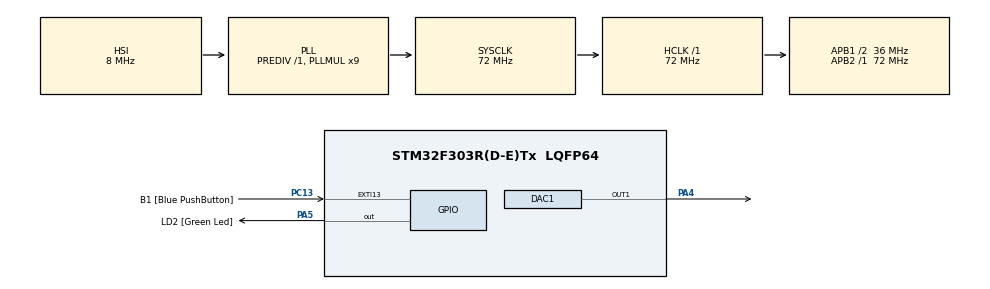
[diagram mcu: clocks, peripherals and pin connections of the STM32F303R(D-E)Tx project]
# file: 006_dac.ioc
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Mcu.Family=STM32F3
RCC.CortexFreq_Value=72000000
PC13.Signal=GPXTI13
PA14.GPIO_Label=TCK
RCC.SYSCLKSourceVirtual=RCC_SYSCLKSOURCE_PLLCLK
PC13.GPIO_Label=B1 [Blue PushButton]
RCC.APB1CLKDivider=RCC_HCLK_DIV2
PC14-OSC32_IN.Signal=RCC_OSC32_IN
ProjectManager.StackSize=0x400
PA13.Signal=SYS_JTMS-SWDIO
ProjectManager.TargetToolchain=STM32CubeIDE
SH.COMP_DAC11_group.0=DAC1_OUT1,DAC_OUT1
RCC.HCLKFreq_Value=72000000
RCC.APB2TimFreq_Value=72000000
RCC.USBFreq_Value=72000000
PC15-OSC32_OUT.Signal=RCC_OSC32_OUT
RCC.AHBFreq_Value=72000000
PF0-OSC_IN.Mode=HSE-External-Oscillator
PA5.Signal=GPIO_Output
RCC.HSE_VALUE=8000000
board=NUCLEO-F303RE
RCC.RCC_PLLsource_Clock_Source_FROM_HSE=RCC_HSE_PREDIV_DIV2
RCC.PLLMUL=RCC_PLL_MUL9
RCC.APB2Freq_Value=72000000
PA14.Mode=Serial_Wire
PA5.GPIO_PuPd=GPIO_NOPULL
PA13.Mode=Serial_Wire
Mcu.Name=STM32F303R(D-E)Tx
PA13.GPIO_Label=TMS
PB3.Signal=SYS_JTDO-TRACESWO
PA4.Signal=COMP_DAC11_group
RCC.SYSCLKFreq_VALUE=72000000
Mcu.Package=LQFP64
PA5.GPIO_Label=LD2 [Green Led]
PC13.GPIO_ModeDefaultEXTI=GPIO_MODE_IT_FALLING
PA14.Signal=SYS_JTCK-SWCLK
ProjectManager.HeapSize=0x200
RCC.HSI_VALUE=8000000
RCC.PLLP=RCC_PLLP_DIV4
PA5.GPIO_Speed=GPIO_SPEED_FREQ_LOW
RCC.PLLQ=7
NVIC.PriorityGroup=NVIC_PRIORITYGROUP_0
RCC.PLLM=8
RCC.PLLN=336
RCC.APB1TimFreq_Value=72000000
PF0-OSC_IN.Signal=RCC_OSC_IN
PF1-OSC_OUT.Mode=HSE-External-Oscillator
RCC.APB1Freq_Value=36000000
PA5.GPIO_Mode=GPIO_MODE_OUTPUT_PP
PF1-OSC_OUT.Signal=RCC_OSC_OUT
PB3.GPIO_Label=SWO

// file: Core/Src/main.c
/* USER CODE BEGIN Header */
/**
  ******************************************************************************
  * @file           : main.c
  * @brief          : Main program body
  ******************************************************************************
  * @attention
  *
  * <h2><center>&copy; Copyright (c) 2021 STMicroelectronics.
  * All rights reserved.</center></h2>
  *
  * This software component is licensed by ST under BSD 3-Clause license,
  * the "License"; You may not use this file except in compliance with the
  * License. You may obtain a copy of the License at:
  *                        opensource.org/licenses/BSD-3-Clause
  *
  ******************************************************************************
  */
/* USER CODE END Header */
#include "main.h"

DAC_HandleTypeDef hdac1;
uint16_t dac_value;

void SystemClock_Config(void);
static void MX_GPIO_Init(void);
static void MX_DAC1_Init(void);

int main(void)
{

  /* MCU Configuration--------------------------------------------------------*/

  /* Reset of all peripherals, Initializes the Flash interface and the Systick. */
  HAL_Init();

  /* Configure the system clock */
  SystemClock_Config();

  /* Initialize all configured peripherals */
  MX_GPIO_Init();
  MX_DAC1_Init();
  /* USER CODE BEGIN 2 */
  HAL_DAC_SetValue(&hdac1, DAC1_CHANNEL_1, DAC_ALIGN_12B_R, 4090);
  HAL_DAC_Start(&hdac1, DAC1_CHANNEL_1);

  /* USER CODE END 2 */

  /* Infinite loop */
  while (1)
  {

    /* USER CODE BEGIN 3 */
	  dac_value=HAL_DAC_GetValue(&hdac1, DAC1_CHANNEL_1);
  }
  /* USER CODE END 3 */
}

void SystemClock_Config(void)
{
  RCC_OscInitTypeDef RCC_OscInitStruct = {0};
  RCC_ClkInitTypeDef RCC_ClkInitStruct = {0};

  /** Initializes the RCC Oscillators according to the specified parameters
  * in the RCC_OscInitTypeDef structure.
  */
  RCC_OscInitStruct.OscillatorType = RCC_OSCILLATORTYPE_HSI;
  RCC_OscInitStruct.HSIState = RCC_HSI_ON;
  RCC_OscInitStruct.HSICalibrationValue = RCC_HSICALIBRATION_DEFAULT;
  RCC_OscInitStruct.PLL.PLLState = RCC_PLL_ON;
  RCC_OscInitStruct.PLL.PLLSource = RCC_PLLSOURCE_HSI;
  RCC_OscInitStruct.PLL.PLLMUL = RCC_PLL_MUL9;
  RCC_OscInitStruct.PLL.PREDIV = RCC_PREDIV_DIV1;
  if (HAL_RCC_OscConfig(&RCC_OscInitStruct) != HAL_OK)
  {
    Error_Handler();
  }
  /** Initializes the CPU, AHB and APB buses clocks
  */
  RCC_ClkInitStruct.ClockType = RCC_CLOCKTYPE_HCLK|RCC_CLOCKTYPE_SYSCLK
                              |RCC_CLOCKTYPE_PCLK1|RCC_CLOCKTYPE_PCLK2;
  RCC_ClkInitStruct.SYSCLKSource = RCC_SYSCLKSOURCE_PLLCLK;
  RCC_ClkInitStruct.AHBCLKDivider = RCC_SYSCLK_DIV1;
  RCC_ClkInitStruct.APB1CLKDivider = RCC_HCLK_DIV2;
  RCC_ClkInitStruct.APB2CLKDivider = RCC_HCLK_DIV1;

  if (HAL_RCC_ClockConfig(&RCC_ClkInitStruct, FLASH_LATENCY_2) != HAL_OK)
  {
    Error_Handler();
  }
}

static void MX_DAC1_Init(void)
{

  DAC_ChannelConfTypeDef sConfig = {0};

  /** DAC Initialization
  */
  hdac1.Instance = DAC1;
  if (HAL_DAC_Init(&hdac1) != HAL_OK)
  {
    Error_Handler();
  }
  /** DAC channel OUT1 config
  */
  sConfig.DAC_Trigger = DAC_TRIGGER_NONE;
  sConfig.DAC_OutputBuffer = DAC_OUTPUTBUFFER_ENABLE;
  if (HAL_DAC_ConfigChannel(&hdac1, &sConfig, DAC_CHANNEL_1) != HAL_OK)
  {
    Error_Handler();
  }

}

static void MX_GPIO_Init(void)
{
  GPIO_InitTypeDef GPIO_InitStruct = {0};

  /* GPIO Ports Clock Enable */
  __HAL_RCC_GPIOC_CLK_ENABLE();
  __HAL_RCC_GPIOF_CLK_ENABLE();
  __HAL_RCC_GPIOA_CLK_ENABLE();
  __HAL_RCC_GPIOB_CLK_ENABLE();

  /*Configure GPIO pin Output Level */
  HAL_GPIO_WritePin(LD2_GPIO_Port, LD2_Pin, GPIO_PIN_RESET);

  /*Configure GPIO pin : B1_Pin */
  GPIO_InitStruct.Pin = B1_Pin;
  GPIO_InitStruct.Mode = GPIO_MODE_IT_FALLING;
  GPIO_InitStruct.Pull = GPIO_NOPULL;
  HAL_GPIO_Init(B1_GPIO_Port, &GPIO_InitStruct);

  /*Configure GPIO pin : LD2_Pin */
  GPIO_InitStruct.Pin = LD2_Pin;
  GPIO_InitStruct.Mode = GPIO_MODE_OUTPUT_PP;
  GPIO_InitStruct.Pull = GPIO_NOPULL;
  GPIO_InitStruct.Speed = GPIO_SPEED_FREQ_LOW;
  HAL_GPIO_Init(LD2_GPIO_Port, &GPIO_InitStruct);

}

void Error_Handler(void)
{
  __disable_irq();
  while (1)
  {
  }
}

/************************ (C) COPYRIGHT STMicroelectronics *****END OF FILE****/
